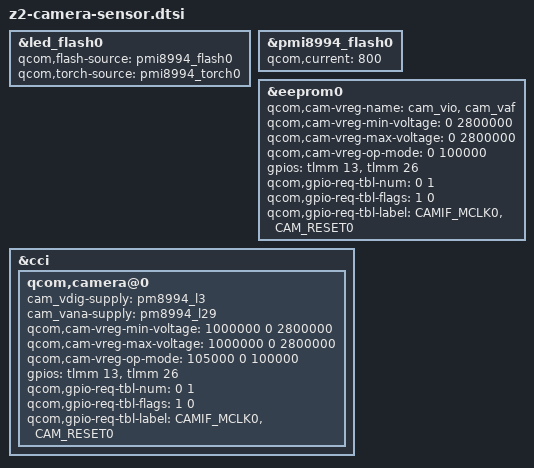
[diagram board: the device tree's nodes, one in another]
&led_flash0 {
	qcom,flash-source = <&pmi8994_flash0>;
	qcom,torch-source = <&pmi8994_torch0>;
};

&pmi8994_flash0 {
	qcom,current = <800>;
};

&eeprom0 {
	/delete-property/ cam_vdig-supply;
	/delete-property/ cam_vana-supply;
	qcom,cam-vreg-name = "cam_vio", "cam_vaf";
	qcom,cam-vreg-min-voltage = <0 2800000>;
	qcom,cam-vreg-max-voltage = <0 2800000>;
	qcom,cam-vreg-op-mode = <0 100000>;
	gpios = <&tlmm 13 0>, <&tlmm 26 0>;
	/delete-property/ qcom,gpio-standby;
	qcom,gpio-req-tbl-num = <0 1>;
	qcom,gpio-req-tbl-flags = <1 0>;
	qcom,gpio-req-tbl-label = "CAMIF_MCLK0", "CAM_RESET0";
	/delete-property/ clocks;
	/delete-property/ clock-names;
	/delete-property/ qcom,clock-rates;
}; 

&cci {
	/delete-node/ qcom,actuator@1;
	/delete-node/ qcom,ois@0;
	qcom,camera@0 {
		/delete-property/ qcom,ois-src;
		cam_vdig-supply = <&pm8994_l3>;
		cam_vana-supply = <&pm8994_l29>;
		qcom,cam-vreg-min-voltage = <1000000 0 2800000>;
		qcom,cam-vreg-max-voltage = <1000000 0 2800000>;
		qcom,cam-vreg-op-mode = <105000 0 100000>;
		gpios = <&tlmm 13 0>, <&tlmm 26 0>;
		/delete-property/qcom,gpio-standby;
		qcom,gpio-req-tbl-num = <0 1>;
		qcom,gpio-req-tbl-flags = <1 0>;
		qcom,gpio-req-tbl-label = "CAMIF_MCLK0", "CAM_RESET0";
		/delete-property/ qcom,clock-rates;
	};
};
